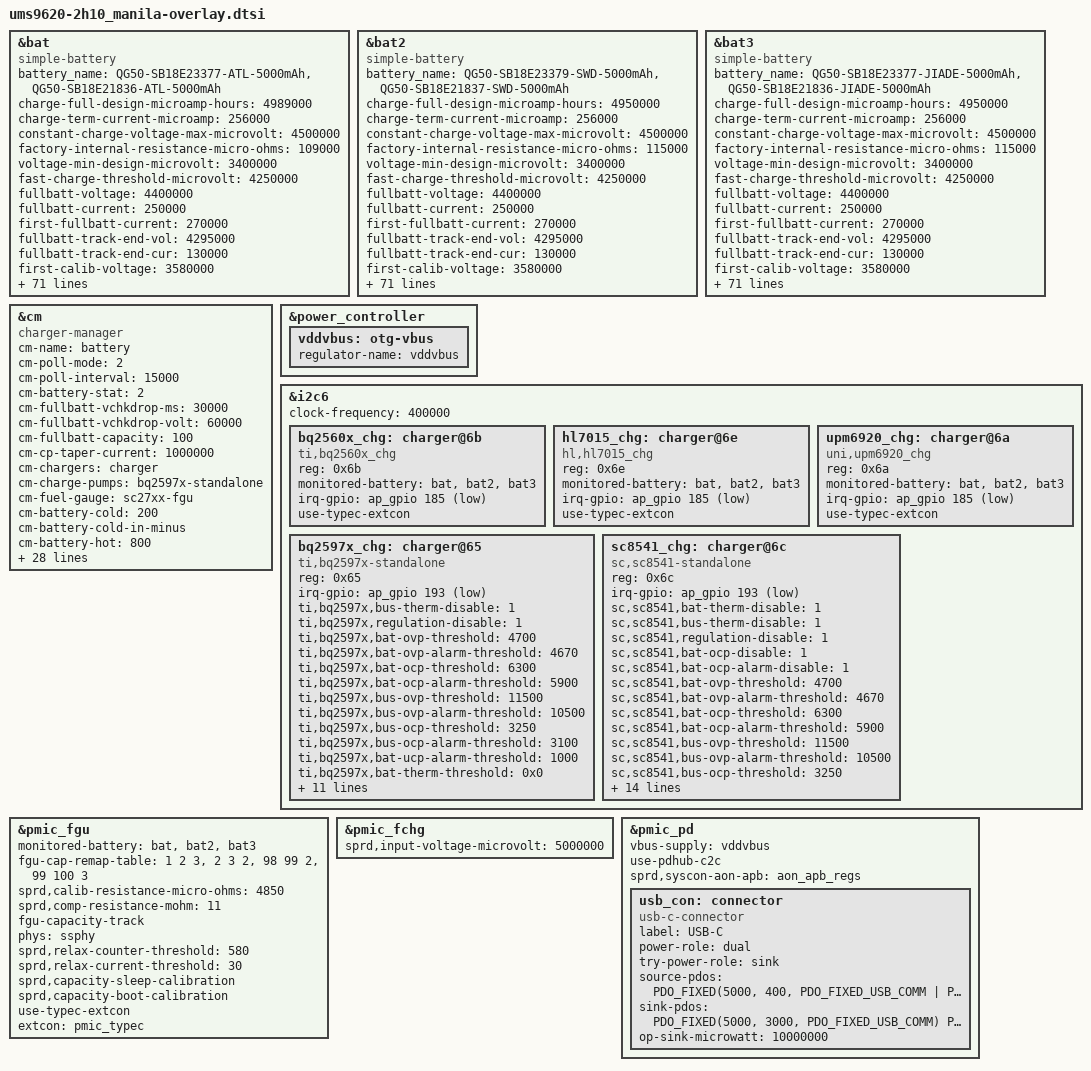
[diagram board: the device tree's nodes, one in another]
// SPDX-License-Identifier: (Licenseref-Unisoc-General-1.0 OR GPL-2.0-only)
/*
 * ums9620-2h10-overlay.dtsi - Unisoc platform device
 *
 * Copyright 2022 Unisoc(Shanghai) Technologies Co.Ltd
 *
 * Licensed under the Unisoc General Software License, version 1.0 (the
 * License);
 * you may not use this file except in compliance with the License.
 * You may obtain a copy of the License at
 * https://www.unisoc.com/en_us/license/UNISOC_GENERAL_LICENSE_V1.0-EN_US
 * Software distributed under the License is distributed on an "AS IS" BASIS,
 * WITHOUT WARRANTIES OF ANY KIND, either express or implied.
 * See the Unisoc General Software License, version 1.0 for more details.
 *
 * Alternatively you can use and distribute this file under the terms of the
 * GNU General Public License version 2, provided that it has to be used
 *  (including but not limited to combining, linking) with any other file under
 * the GNU General Public License version 2 on platforms that use Unisoc Chips.
 */

#include <dt-bindings/usb/pd.h>

&bat {
	compatible = "simple-battery";
	status = "okay";
	battery_name ="QG50-SB18E23377-ATL-5000mAh","QG50-SB18E21836-ATL-5000mAh";

	charge-full-design-microamp-hours = <4989000>;
	charge-term-current-microamp = <256000>;
	constant-charge-voltage-max-microvolt = <4500000>;
	factory-internal-resistance-micro-ohms = <109000>;
	voltage-min-design-microvolt = <3400000>;

	fast-charge-threshold-microvolt = <4250000>;
	fullbatt-voltage = <4400000>;
	fullbatt-current = <250000>;
	first-fullbatt-current = <270000>;
	fullbatt-track-end-vol = <4295000>;
	fullbatt-track-end-cur = <130000>;
	first-calib-voltage = <3580000>;
	first-calib-capacity = <50>;

	ir-cv-offset-microvolt = <100000>;
	ir-rc-micro-ohms = <10000>;
	ir-us-upper-limit-microvolt = <4530000>;

	ocv-capacity-celsius = <25>;
	ocv-capacity-table-0 = <4449000 100>, <4382000 95>, <4328000 90>,
				<4270000 85>, <4210000 80>, <4151000 75>,
				<4095000 70>, <4043000 65>, <3997000 60>,
				<3948000 55>, <3890000 50>, <3859000 45>,
				<3835000 40>, <3815000 35>, <3799000 30>,
				<3779000 25>, <3755000 20>, <3731000 15>,
				<3698000 10>, <3689000 5>, <3400000 0>;
	voltage-temp-table = <1307000 700>, <1203000 750>, <1095000 800>, <986000 850>, <878000 900>,
	      <775000 950>, <678000 1000>, <590000 1050>,
	      <510000 1100>, <440000 1150>, <378000 1200>,
	      <324000 1250>, <278000 1300>, <238000 1350>,
	      <204000 1400>, <175000 1450>, <150000 1500>,
	      <129000 1550>, <111000 1600>, <96000 1650> , <83000 1700>,<63000 1800>;
	capacity-temp-table = <45 100>, <25 100>, <10 100>, <0 92>, <(-10) 84>;
	resistance-temp-table = <45 86>, <25 100>, <10 165>, <0 1067>, <(-10) 1184>;
	charge-sdp-current-microamp = <540000 500000>;
	charge-dcp-current-microamp = <2200000 2100000>;
	charge-cdp-current-microamp = <1500000 1500000>;
	charge-unknown-current-microamp = <1000000 1000000>;
	charge-fchg-current-microamp = <4000000 2000000>;
	charge-flash-current-microamp = <6000000 3000000>;

	cap-calib-energy-density-ocv-table = <3350000 3800000>, <4150000 4350000>;
	cap-track-energy-density-ocv-table = <3400000 3722000>;

	dcp-jeita-temp-table = <800 830 0 4200000>, <1000 1030 1000000 4200000>, <1100 1120 1000000 4500000>,<1150 1170 2200000 4500000>,
		<1450 1420 2200000 4500000>, <1550 1520 2200000 4200000>;
	sdp-jeita-temp-table = <800 830 0 4200000>,  <1000 1030 540000 4200000>,  <1100 1120 540000  4500000>, <1150 1170 540000  4500000>,
		<1450 1420 540000 4500000>, <1550 1520 540000 4200000>;
	cdp-jeita-temp-table = <800 830 0 4200000>, <1000 1030 1000000 4200000>, <1100 1120 1000000 4500000>, <1150 1170 1500000 4500000>,
		<1450 1420 1500000 4500000>, <1550 1520 1500000 4200000>;
	unknown-jeita-temp-table = <800 830 0 4200000>,<1000 1030 1000000 4200000>, <1100 1120 1000000 4500000>,<1150 1170 1000000 4500000>,
		<1450 1420 1000000 4500000>, <1550 1520 1000000 4200000>;
	fchg-jeita-temp-table = <800 830 0 4200000>,<1000 1030 1000000 4200000>, <1100 1120 1000000 4500000>, <1150 1170 3000000 4500000>,
		<1450 1420 4000000 4500000>, <1550 1520 4000000 4200000>;
	flash-jeita-temp-table = <800 830 0 4200000>,<1000 1030 1000000 4200000>, <1100 1120 1000000 4500000>,<1150 1170 3000000 4500000>,
		<1450 1420 6000000 4500000>, <1550 1520 4000000 4200000>;
};

&bat2 {
	compatible = "simple-battery";
	status = "okay";
	battery_name ="QG50-SB18E23379-SWD-5000mAh","QG50-SB18E21837-SWD-5000mAh";

	charge-full-design-microamp-hours = <4950000>;
	charge-term-current-microamp = <256000>;
	constant-charge-voltage-max-microvolt = <4500000>;
	factory-internal-resistance-micro-ohms = <115000>;
	voltage-min-design-microvolt = <3400000>;

	fast-charge-threshold-microvolt = <4250000>;
	fullbatt-voltage = <4400000>;
	fullbatt-current = <250000>;
	first-fullbatt-current = <270000>;
	fullbatt-track-end-vol = <4295000>;
	fullbatt-track-end-cur = <130000>;
	first-calib-voltage = <3580000>;
	first-calib-capacity = <50>;

	ir-cv-offset-microvolt = <100000>;
	ir-rc-micro-ohms = <10000>;
	ir-us-upper-limit-microvolt = <4530000>;

	ocv-capacity-celsius = <25>;
	ocv-capacity-table-0 = <4383000 100>, <4254000 95>, <4201000 90>,
				<4151000 85>, <4102000 80>, <4060000 75>,
				<4006000 70>, <3973000 65>, <3930000 60>,
				<3882000 55>, <3851000 50>, <3829000 45>,
				<3810000 40>, <3795000 35>, <3781000 30>,
				<3765000 25>, <3746000 20>, <3722000 15>,
				<3694000 10>, <3682000 5>, <3400000 0>;
	voltage-temp-table = <1307000 700>, <1203000 750>, <1095000 800>, <986000 850>, <878000 900>,
	      <775000 950>, <678000 1000>, <590000 1050>,
	      <510000 1100>, <440000 1150>, <378000 1200>,
	      <324000 1250>, <278000 1300>, <238000 1350>,
	      <204000 1400>, <175000 1450>, <150000 1500>,
	      <129000 1550>, <111000 1600>, <96000 1650> , <83000 1700>,<63000 1800>;
	capacity-temp-table = <45 100>, <25 100>, <10 100>, <0 95>, <(-10) 90>;
	resistance-temp-table = <45 53>, <25 100>, <10 395>, <0 567>, <(-10) 793>;
	charge-sdp-current-microamp = <540000 500000>;
	charge-dcp-current-microamp = <2200000 2100000>;
	charge-cdp-current-microamp = <1500000 1500000>;
	charge-unknown-current-microamp = <1000000 1000000>;
	charge-fchg-current-microamp = <4000000 2000000>;
	charge-flash-current-microamp = <6000000 3000000>;

	cap-calib-energy-density-ocv-table = <3350000 3800000>, <4150000 4350000>;
	cap-track-energy-density-ocv-table = <3400000 3722000>;

	dcp-jeita-temp-table = <800 830 0 4200000>, <1000 1030 1000000 4200000>, <1100 1120 1000000 4500000>,<1150 1170 2200000 4500000>,
		<1450 1420 2200000 4500000>, <1550 1520 2200000 4200000>;
	sdp-jeita-temp-table = <800 830 0 4200000>,  <1000 1030 540000 4200000>,  <1100 1120 540000  4500000>, <1150 1170 540000  4500000>,
		<1450 1420 540000 4500000>, <1550 1520 540000 4200000>;
	cdp-jeita-temp-table = <800 830 0 4200000>, <1000 1030 1000000 4200000>, <1100 1120 1000000 4500000>, <1150 1170 1500000 4500000>,
		<1450 1420 1500000 4500000>, <1550 1520 1500000 4200000>;
	unknown-jeita-temp-table = <800 830 0 4200000>,<1000 1030 1000000 4200000>, <1100 1120 1000000 4500000>,<1150 1170 1000000 4500000>,
		<1450 1420 1000000 4500000>, <1550 1520 1000000 4200000>;
	fchg-jeita-temp-table = <800 830 0 4200000>,<1000 1030 1000000 4200000>, <1100 1120 1000000 4500000>, <1150 1170 3000000 4500000>,
		<1450 1420 4000000 4500000>, <1550 1520 4000000 4200000>;
	flash-jeita-temp-table = <800 830 0 4200000>,<1000 1030 1000000 4200000>, <1100 1120 1000000 4500000>,<1150 1170 3000000 4500000>,
		<1450 1420 6000000 4500000>, <1550 1520 4000000 4200000>;
};

&bat3 {
	compatible = "simple-battery";
	status = "okay";
	battery_name ="QG50-SB18E23377-JIADE-5000mAh","QG50-SB18E21836-JIADE-5000mAh";

	charge-full-design-microamp-hours = <4950000>;
	charge-term-current-microamp = <256000>;
	constant-charge-voltage-max-microvolt = <4500000>;
	factory-internal-resistance-micro-ohms = <115000>;
	voltage-min-design-microvolt = <3400000>;

	fast-charge-threshold-microvolt = <4250000>;
	fullbatt-voltage = <4400000>;
	fullbatt-current = <250000>;
	first-fullbatt-current = <270000>;
	fullbatt-track-end-vol = <4295000>;
	fullbatt-track-end-cur = <130000>;
	first-calib-voltage = <3580000>;
	first-calib-capacity = <50>;

	ir-cv-offset-microvolt = <100000>;
	ir-rc-micro-ohms = <10000>;
	ir-us-upper-limit-microvolt = <4530000>;

	ocv-capacity-celsius = <25>;
	ocv-capacity-table-0 = <4383000 100>, <4254000 95>, <4201000 90>,
				<4151000 85>, <4102000 80>, <4060000 75>,
				<4006000 70>, <3973000 65>, <3930000 60>,
				<3882000 55>, <3851000 50>, <3829000 45>,
				<3810000 40>, <3795000 35>, <3781000 30>,
				<3765000 25>, <3746000 20>, <3722000 15>,
				<3694000 10>, <3682000 5>, <3400000 0>;
	voltage-temp-table = <1307000 700>, <1203000 750>, <1095000 800>, <986000 850>, <878000 900>,
	      <775000 950>, <678000 1000>, <590000 1050>,
	      <510000 1100>, <440000 1150>, <378000 1200>,
	      <324000 1250>, <278000 1300>, <238000 1350>,
	      <204000 1400>, <175000 1450>, <150000 1500>,
	      <129000 1550>, <111000 1600>, <96000 1650> , <83000 1700>,<63000 1800>;
	capacity-temp-table = <45 100>, <25 100>, <10 100>, <0 95>, <(-10) 90>;
	resistance-temp-table = <45 53>, <25 100>, <10 395>, <0 567>, <(-10) 793>;
	charge-sdp-current-microamp = <540000 500000>;
	charge-dcp-current-microamp = <2200000 2100000>;
	charge-cdp-current-microamp = <1500000 1500000>;
	charge-unknown-current-microamp = <1000000 1000000>;
	charge-fchg-current-microamp = <4000000 2000000>;
	charge-flash-current-microamp = <6000000 3000000>;

	cap-calib-energy-density-ocv-table = <3350000 3800000>, <4150000 4350000>;
	cap-track-energy-density-ocv-table = <3400000 3722000>;

	dcp-jeita-temp-table = <800 830 0 4200000>, <1000 1030 1000000 4200000>, <1100 1120 1000000 4500000>,<1150 1170 2200000 4500000>,
		<1450 1420 2200000 4500000>, <1550 1520 2200000 4200000>;
	sdp-jeita-temp-table = <800 830 0 4200000>,  <1000 1030 540000 4200000>,  <1100 1120 540000  4500000>, <1150 1170 540000  4500000>,
		<1450 1420 540000 4500000>, <1550 1520 540000 4200000>;
	cdp-jeita-temp-table = <800 830 0 4200000>, <1000 1030 1000000 4200000>, <1100 1120 1000000 4500000>, <1150 1170 1500000 4500000>,
		<1450 1420 1500000 4500000>, <1550 1520 1500000 4200000>;
	unknown-jeita-temp-table = <800 830 0 4200000>,<1000 1030 1000000 4200000>, <1100 1120 1000000 4500000>,<1150 1170 1000000 4500000>,
		<1450 1420 1000000 4500000>, <1550 1520 1000000 4200000>;
	fchg-jeita-temp-table = <800 830 0 4200000>,<1000 1030 1000000 4200000>, <1100 1120 1000000 4500000>, <1150 1170 3000000 4500000>,
		<1450 1420 4000000 4500000>, <1550 1520 4000000 4200000>;
	flash-jeita-temp-table = <800 830 0 4200000>,<1000 1030 1000000 4200000>, <1100 1120 1000000 4500000>,<1150 1170 3000000 4500000>,
		<1450 1420 6000000 4500000>, <1550 1520 4000000 4200000>;
};
&cm {
	compatible = "charger-manager";
	status = "okay";
	cm-name = "battery";
	cm-poll-mode = <2>;
	cm-poll-interval = <15000>;
	cm-battery-stat = <2>;

	cm-fullbatt-vchkdrop-ms = <30000>;
	cm-fullbatt-vchkdrop-volt = <60000>;
	cm-fullbatt-capacity = <100>;
	/*Charge pump target charge current*/
	cm-cp-taper-current = <1000000>;

	cm-chargers = "charger";
	cm-charge-pumps = "bq2597x-standalone";
	cm-fuel-gauge = "sc27xx-fgu";

	/* in deci centigrade */
	cm-battery-cold = <200>;
	cm-battery-cold-in-minus;
	cm-battery-hot = <800>;
	cm-battery-temp-diff = <100>;

	/* Allow charging for 6hr */
	cm-charging-max = <21600000>;
	/* recovery charging after stop charging 45min */
	cm-discharging-max = <2700000>;

	/* the interval to feed charger watchdog */
	cm-wdt-interval = <60>;

	/* drop voltage in microVolts to allow shutdown */
	cm-shutdown-voltage = <3100000>;

	/* when 99% of the time is exceeded, it will be forced to 100% */
	cm-tickle-time-out = <1500>;

	/* how much time to allow capacity change */
	cm-one-cap-time = <30>;

	cm-thermal-zone = "board-thmzone";

	/* when the safe charging voltage is exceeded, stop charging */
	cm-charge-voltage-max = <6500000>;
	cm-fast-charge-voltage-max = <10500000>;
	cm-flash-charge-voltage-max = <12500000>;
	/* drop voltage in microVolts to restart charging */
	cm-charge-voltage-drop = <700000>;
	cm-fast-charge-voltage-drop = <700000>;
	cm-flash-charge-voltage-drop = <1000000>;

	/* sprd_fchg parameter */
	sprd,support-fchg;
	sprd,support-pd-pps;
	sprd,pd-fixed-max-microwatt = <18000000>;
	sprd,customized-fchg-psy ="bq2560xpe_charger","bq2560xqc_charger","hl7015qc_charger","upm6920qc_charger";

	monitored-battery = <&bat>,<&bat2>,<&bat3>;
	cm-capacity-track;
	cm-keep-awake;
	cm-support-linear-charge;

	phys = <&ssphy>;
	pd-extcon-enable;
	extcon = <&pmic_typec>, <&pmic_pd>;
	use-typec-extcon;
};

&power_controller {
	vddvbus:otg-vbus {
		regulator-name = "vddvbus";
	};
};

&i2c6 {
	#address-cells = <1>;
	#size-cells = <0>;

	status = "okay";
	bq2560x_chg: charger@6b {
		compatible = "ti,bq2560x_chg";
		reg = <0x6b>;
		monitored-battery = <&bat>,<&bat2>,<&bat3>;
		irq-gpio = <&ap_gpio 185 GPIO_ACTIVE_LOW>;
		use-typec-extcon;
	};
	hl7015_chg: charger@6e {
		compatible = "hl,hl7015_chg";
		reg = <0x6e>;
		monitored-battery = <&bat>,<&bat2>,<&bat3>;
		irq-gpio = <&ap_gpio 185 GPIO_ACTIVE_LOW>;
		use-typec-extcon;
	};
	upm6920_chg: charger@6a {
		compatible = "uni,upm6920_chg";
		reg = <0x6a>;
		monitored-battery = <&bat>,<&bat2>,<&bat3>;
		irq-gpio = <&ap_gpio 185 GPIO_ACTIVE_LOW>;
		use-typec-extcon;
	};
};

&i2c6 {
	status = "okay";
	clock-frequency = <400000>;

	bq2597x_chg: charger@65 {
		compatible = "ti,bq2597x-standalone";
		reg = <0x65>;
		irq-gpio = <&ap_gpio 193 GPIO_ACTIVE_LOW>;

		ti,bq2597x,bus-therm-disable = <1>;
		ti,bq2597x,regulation-disable = <1>;

		ti,bq2597x,bat-ovp-threshold = <4700>;
		ti,bq2597x,bat-ovp-alarm-threshold = <4670>;
		ti,bq2597x,bat-ocp-threshold = <6300>;
		ti,bq2597x,bat-ocp-alarm-threshold = <5900>;

		ti,bq2597x,bus-ovp-threshold = <11500>;
		ti,bq2597x,bus-ovp-alarm-threshold = <10500>;
		ti,bq2597x,bus-ocp-threshold = <3250>;
		ti,bq2597x,bus-ocp-alarm-threshold = <3100>;

		ti,bq2597x,bat-ucp-alarm-threshold = <1000>;

		ti,bq2597x,bat-therm-threshold = <0x0>;
		ti,bq2597x,bus-therm-threshold = <0x0>;
		ti,bq2597x,die-therm-threshold = <0xc8>;

		ti,bq2597x,ac-ovp-threshold = <13>;
		ti,bq2597x,sense-resistor-mohm = <5>;
		ti,bq2597x,adc-sample-bits = <13>;
		ti,bq2597x,ibat-regulation-threshold = <300>;
		ti,bq2597x,vbat-regulation-threshold = <100>;
		ti,bq2597x,vdrop-threshold = <400>;
		ti,bq2597x,vdrop-deglitch = <5000>;
		ti,bq2597x,ss-timeout = <100000>;
		ti,bq2597x,watchdog-timer = <30000>;
	};
	sc8541_chg: charger@6c {
		compatible = "sc,sc8541-standalone";
		reg = <0x6c>;
		irq-gpio = <&ap_gpio 193 GPIO_ACTIVE_LOW>;

		sc,sc8541,bat-therm-disable = <1>;
		sc,sc8541,bus-therm-disable = <1>;
		sc,sc8541,regulation-disable = <1>;

		sc,sc8541,bat-ocp-disable = <1>;
		sc,sc8541,bat-ocp-alarm-disable= <1>;

		sc,sc8541,bat-ovp-threshold = <4700>;
		sc,sc8541,bat-ovp-alarm-threshold = <4670>;
		sc,sc8541,bat-ocp-threshold = <6300>;
		sc,sc8541,bat-ocp-alarm-threshold = <5900>;

		sc,sc8541,bus-ovp-threshold = <11500>;
		sc,sc8541,bus-ovp-alarm-threshold = <10500>;
		sc,sc8541,bus-ocp-threshold = <3250>;
		sc,sc8541,bus-ocp-alarm-threshold = <3100>;

		sc,sc8541,bat-ucp-alarm-threshold = <1000>;

		sc,sc8541,bat-therm-threshold = <0x0>;
		sc,sc8541,bus-therm-threshold = <0x0>;
		sc,sc8541,die-therm-threshold = <152>;

		sc,sc8541,ac-ovp-threshold = <13>;
		sc,sc8541,sense-resistor-mohm = <5>;
		sc,sc8541,adc-sample-bits = <12>;
		sc,sc8541,ibat-regulation-threshold = <300>;
		sc,sc8541,vbat-regulation-threshold = <100>;
		sc,sc8541,vdrop-threshold = <400>;
		sc,sc8541,vdrop-deglitch = <5000>;
		sc,sc8541,ss-timeout = <100000>;
		sc,sc8541,watchdog-timer = <30000>;
	};
};

&pmic_fgu {
	monitored-battery = <&bat>,<&bat2>,<&bat3>;
	fgu-cap-remap-table = <1 2 3>, <2 3 2>, <98 99 2>, <99 100 3>;
	sprd,calib-resistance-micro-ohms = <4850>;
	sprd,comp-resistance-mohm = <11>;

	fgu-capacity-track;
	phys = <&ssphy>;

	sprd,relax-counter-threshold = <580>;
	sprd,relax-current-threshold = <30>;
	sprd,capacity-sleep-calibration;

	sprd,capacity-boot-calibration;
	use-typec-extcon;
	extcon = <&pmic_typec>;
};

&pmic_fchg {
	status = "okay";
	sprd,input-voltage-microvolt = <5000000>;
};

&pmic_pd {
	status = "okay";
	vbus-supply = <&vddvbus>;
	use-pdhub-c2c;
	sprd,syscon-aon-apb = <&aon_apb_regs>;
	usb_con: connector {
		compatible = "usb-c-connector";
		label = "USB-C";
		power-role = "dual";
		try-power-role = "sink";
		source-pdos = <PDO_FIXED(5000, 400, PDO_FIXED_USB_COMM |
				PDO_FIXED_DUAL_ROLE | PDO_FIXED_DATA_SWAP)>;
		sink-pdos = <PDO_FIXED(5000, 3000, PDO_FIXED_USB_COMM)
				PDO_PPS_APDO(3300, 11000, 3000)>;
		op-sink-microwatt = <10000000>;
	};
};
